# M07_ResetManager register map
Vendor: Babel; File version: 1.0
M07_ResetManager Register Map
CPU: CM0 r0p0, little endian, no MPU, no FPU
Registers are 32-bit, read-write, reset 0xE unless marked. A register's access mark holds for its fields unless they carry their own. Offsets are from the block's base; lines under a group give offsets from that group; [hi:lo] are bit positions; {n}, {i} and the like mark numbered series; 'fields as' and 'values as' point back to an identical list; <NAME> marks a mode.

## Memory map
0x00000000 M07_ResetManager

## M07_ResetManager
Base 0x00000000
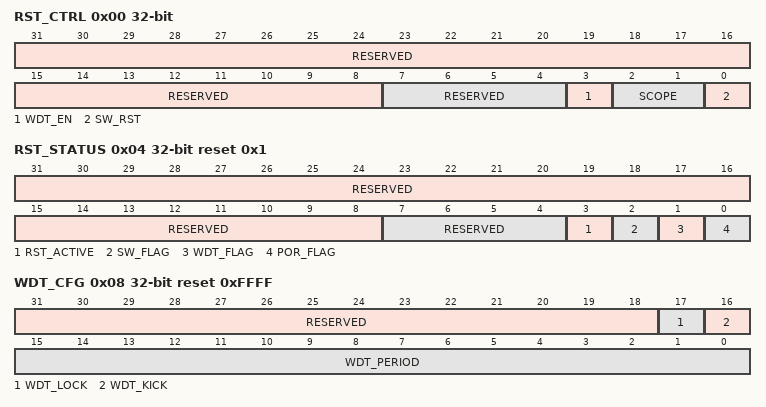
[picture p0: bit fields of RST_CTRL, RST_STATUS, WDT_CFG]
0x00 RST_CTRL — 复位控制：软件复位触发、复位范围、WDT 使能
  [31:8] RESERVED - — 保留，必须写 0
  [7:4] RESERVED - — 保留，必须写 0
  [3] WDT_EN — WDT 复位使能。1=使能，0=禁用
  [2:1] SCOPE — 复位范围。00=仅 sys，01=main+sys，11=全局
  [0] SW_RST w1s — 软件复位触发。写 1 触发复位，自动清零
0x04 RST_STATUS ro reset 0x1 — 复位状态：复位源标志、当前复位输出状态
  [31:8] RESERVED - — 保留
  [7:4] RESERVED - — 保留
  [3] RST_ACTIVE — 当前复位输出状态（任一复位源有效时为 1）
  [2] SW_FLAG — 上次复位由软件触发
  [1] WDT_FLAG — 上次复位由 WDT（看门狗）触发
  [0] POR_FLAG — 上次复位由 POR（上电复位）触发
0x08 WDT_CFG reset 0xFFFF — 看门狗配置：超时周期、喂狗、锁定
  [31:18] RESERVED - — 保留，必须写 0
  [17] WDT_LOCK — WDT_PERIOD 锁定。写 1 锁定，需 POR 解锁
  [16] WDT_KICK w1s — 喂狗操作。写 1 重置计数器，自动清零
  [15:0] WDT_PERIOD — 看门狗超时周期（CLK_AON 计数值）
